# AT32M416xx_v2 register map
Vendor: Keil; Series: AT32M416; File version: 1.0
CPU: CM4 r0p1, little endian, no MPU, FPU, 4 interrupt priority bits
Registers are 32-bit, read-write, reset 0x0 unless marked. A register's access mark holds for its fields unless they carry their own. Offsets are from the block's base; [hi:lo] are bit positions.

## TMR9 — General purpose timer
Base 0x40014000
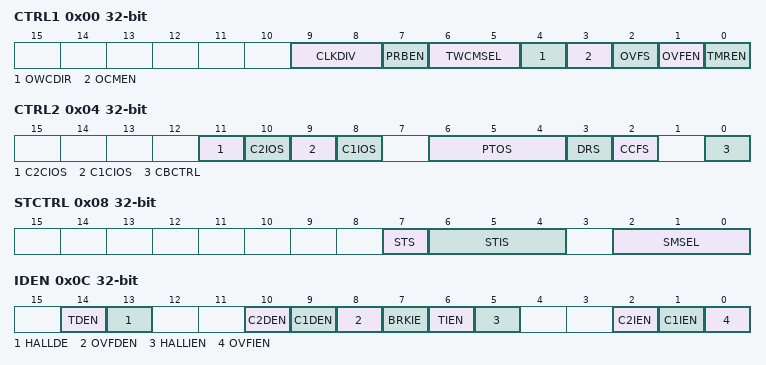
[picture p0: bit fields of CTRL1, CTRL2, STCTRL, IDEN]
0x00 CTRL1 — Control register 1
  [9:8] CLKDIV — Clock divider
  [7] PRBEN — Period buffer enable
  [6:5] TWCMSEL — Two-way count mode selection
  [4] OWCDIR — One-way count direction
  [3] OCMEN — One cycle mode enable
  [2] OVFS — Overflow event source
  [1] OVFEN — Overflow event enable
  [0] TMREN — TMR enable
0x04 CTRL2 — Control register 2
  [11] C2CIOS — Channel 2 complementary idle output state
  [10] C2IOS — Channel 2 idle output state
  [9] C1CIOS — Channel 1 complementary idle output state
  [8] C1IOS — Channel 1 idle output state
  [6:4] PTOS — Primary TMR output selection
  [3] DRS — DMA request source
  [2] CCFS — Channel control bit refresh select
  [0] CBCTRL — Channel buffer control
0x08 STCTRL — Subordinate TMR control register
  [7] STS — Subordinate TMR synchronization
  [6:4] STIS — Subordinate TMR input selection
  [2:0] SMSEL — Subordinate TMR mode selection
0x0C IDEN — Interrupt/DMA enable register
  [14] TDEN — Trigger DMA request enable
  [13] HALLDE — HALL DMA request enable
  [10] C2DEN — Channel 2 DMA request enable
  [9] C1DEN — Channel 1 DMA request enable
  [8] OVFDEN — Overflow DMA request enable
  [7] BRKIE — Brake interrupt enable
  [6] TIEN — Trigger interrupt enable
  [5] HALLIEN — HALL interrupt enable
  [2] C2IEN — Channel 2 interrupt enable
  [1] C1IEN — Channel 1 interrupt enable
  [0] OVFIEN — Overflow interrupt enable
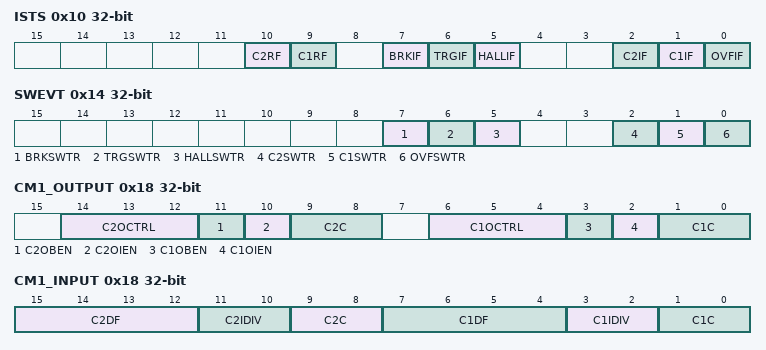
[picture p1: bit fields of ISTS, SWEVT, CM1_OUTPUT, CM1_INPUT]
0x10 ISTS — Interrupt status register
  [10] C2RF — Channel 2 recapture flag
  [9] C1RF — Channel 1 recapture flag
  [7] BRKIF — Brake interrupt flag
  [6] TRGIF — Trigger interrupt flag
  [5] HALLIF — HALL interrupt flag
  [2] C2IF — Channel 2 interrupt flag
  [1] C1IF — Channel 1 interrupt flag
  [0] OVFIF — Overflow interrupt flag
0x14 SWEVT — Software event register
  [7] BRKSWTR — Brake event triggered by software
  [6] TRGSWTR — Trigger event triggered by software
  [5] HALLSWTR — HALL event triggered by software
  [2] C2SWTR — Channel 2 event triggered by software
  [1] C1SWTR — Channel 1 event triggered by software
  [0] OVFSWTR — Overflow event triggered by software
0x18 CM1_OUTPUT — Channel output mode register
  [14:12] C2OCTRL — Channel 2 output control
  [11] C2OBEN — Channel 2 output buffer enable
  [10] C2OIEN — Channel 2 output immediately enable
  [9:8] C2C — Channel 2 configure
  [6:4] C1OCTRL — Channel 1 output control
  [3] C1OBEN — Channel 1 output buffer enable
  [2] C1OIEN — Channel 1 output immediately enable
  [1:0] C1C — Channel 1 configure
0x18 CM1_INPUT (alternate view of CM1_OUTPUT) — Channel input mode register 1
  [15:12] C2DF — Channel 2 digital filter
  [11:10] C2IDIV — Channel 2 input divider
  [9:8] C2C — Channel 2 configure
  [7:4] C1DF — Channel 1 digital filter
  [3:2] C1IDIV — Channel 1 input divider
  [1:0] C1C — Channel 1 configure
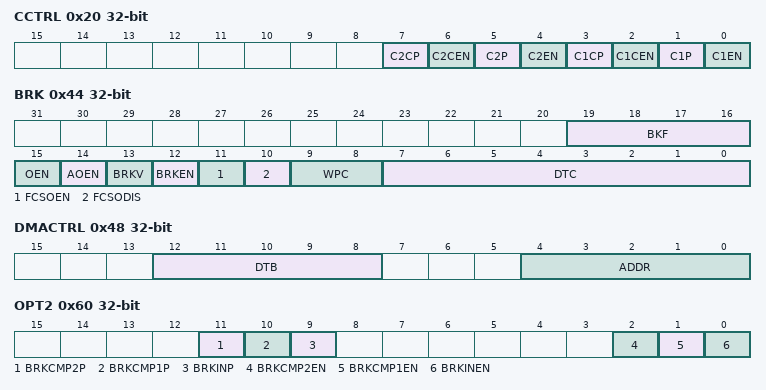
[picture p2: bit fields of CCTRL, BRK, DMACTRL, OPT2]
0x20 CCTRL — Channel control register
  [7] C2CP — Channel 2 complementary polarity
  [6] C2CEN — Channel 2 complementary enable
  [5] C2P — Channel 2 Polarity
  [4] C2EN — Channel 2 enable
  [3] C1CP — Channel 1 complementary polarity
  [2] C1CEN — Channel 1 complementary enable
  [1] C1P — Channel 1 Polarity
  [0] C1EN — Channel 1 enable
0x24 CVAL — Counter value
  [15:0] CVAL
0x28 DIV — Divider value
  [15:0] DIV
0x2C PR — Period value
  [15:0] PR
0x30 RPR — Repetition of period value
  [7:0] RPR
0x34 C1DT — Channel 1 data register
  [15:0] C1DT
0x38 C2DT — Channel 2 data register
  [15:0] C2DT
0x44 BRK — Brake register
  [19:16] BKF — brake input filter
  [15] OEN — Output enable
  [14] AOEN — Automatic output enable
  [13] BRKV — Brake input validity
  [12] BRKEN — Brake enable
  [11] FCSOEN — Frozen channel status when holistic output enable
  [10] FCSODIS — Frozen channel status when holistic output disable
  [9:8] WPC — Write protected configuration
  [7:0] DTC — Dead-time configuration
0x48 DMACTRL — DMA control register
  [12:8] DTB — DMA transfer bytes
  [4:0] ADDR — DMA transfer address offset
0x4C DMADT — DMA data register
  [15:0] DMADT
0x60 OPT2 — option 2 register
  [11] BRKCMP2P — BRK CMP2 input polarity
  [10] BRKCMP1P — BRK CMP1 input polarity
  [9] BRKINP — BRK BKIN input polarity
  [2] BRKCMP2EN — BRK CMP2 enable
  [1] BRKCMP1EN — BRK CMP1 enable
  [0] BRKINEN — BRK BKIN enable
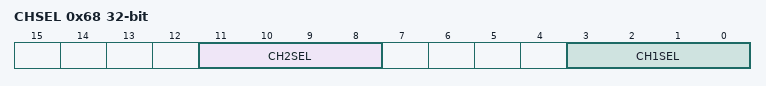
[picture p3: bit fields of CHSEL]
0x68 CHSEL — channel input selection register
  [11:8] CH2SEL — CH2 input selection
  [3:0] CH1SEL — CH1 input selection

## TMR10 — General purpose timer
Base 0x40014400
Same registers: TMR11 0x40014800
Registers as TMR9; these are added or differ:
0x68 CHSEL — channel input selection register
  [3:0] CH1SEL — CH1 input selection
